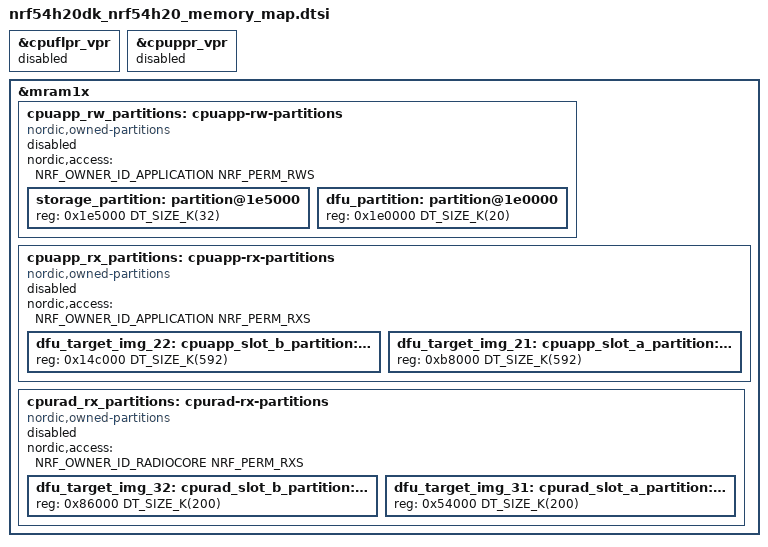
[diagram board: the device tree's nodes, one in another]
/*
 * Copyright (c) 2025 Nordic Semiconductor ASA
 *
 * SPDX-License-Identifier: LicenseRef-Nordic-5-Clause
 */

/* Disable FLPR and PPR cores */
&cpuflpr_vpr {
	status = "disabled";
	/delete-property/ source-memory;
};

&cpuppr_vpr {
	status = "disabled";
	/delete-property/ source-memory;
};

/* Override all application and radio partitions */
/delete-node/ &cpurad_rx_partitions;
/delete-node/ &cpuapp_rx_partitions;
/delete-node/ &cpuapp_rw_partitions;

/**
 * nRF54H20 MRAM area from 0x54000 to 0x1ED000 can be partitioned according to
 * specific end product needs. This file shows how to completely redefine all
 * partitions in mentioned area. For convenience, partition(s) unrelated to
 * DFU/boot (i.e. storage_partition, utilized for application settings)
 * are also reflected.
 *
 * Attention! Partitions are not updateable over the air, therefore must be
 * defined in a way that anticipated future image grow is reflected.
 *
 * ________________________ 0x200000
 * | Nordic (reserved)    |    76 kB
 * +----------------------+ 0x1ed000
 * | Application (RWS)    |
 * |  __________________  |
 * | | Settings/storage | |    32 kB
 * | +------------------+ | 0x1e5000
 * | | DFU partition    | |
 * | |__________________| |    20 kB
 * +----------------------+ 0x1e0000
 * | Application (RXS)    |
 * |  ___________________ |
 * | | Slot B           | |   592 kB
 * | +------------------+ | 0x14c000
 * | | Slot A           | |
 * | |__________________| |   592 kB
 * +----------------------+ 0x0b8000
 * | Radio (RXS)          |
 * |  ___________________ |
 * | | Slot B           | |   200 kB
 * | +------------------+ | 0x086000
 * | | Slot A           | |
 * | |__________________| |   200 kB
 * +----------------------+ 0x054000
 * | Nordic (reserved)    |   336 kB
 * |______________________| 0x000000
 */

&mram1x {
	cpuapp_rw_partitions: cpuapp-rw-partitions {
		compatible = "nordic,owned-partitions", "fixed-partitions";
		status = "disabled";
		nordic,access = <NRF_OWNER_ID_APPLICATION NRF_PERM_RWS>;
		#address-cells = <1>;
		#size-cells = <1>;

		/* Application-controlled NVM data. Size/location should be adjusted
		 * to end-product needs. Partition can be completely removed if
		 * it is not needed by the end product.
		 */
		storage_partition: partition@1e5000 {
			reg = < 0x1e5000 DT_SIZE_K(32) >;
		};

		/* DFU Partition shall be large enough to hold an envelope with candidate
		 * manifests. It is not recommended to decrease it below proposed 20kB,
		 * as it may affect device updateability.
		 */
		dfu_partition: partition@1e0000 {
			reg = < 0x1e0000 DT_SIZE_K(20) >;
		};
	};

	cpuapp_rx_partitions: cpuapp-rx-partitions {
		compatible = "nordic,owned-partitions", "fixed-partitions";
		status = "disabled";
		nordic,access = <NRF_OWNER_ID_APPLICATION NRF_PERM_RXS>;
		#address-cells = < 0x1 >;
		#size-cells = < 0x1 >;

		dfu_target_img_22: cpuapp_slot_b_partition: partition@14c000 {
			reg = < 0x14c000 DT_SIZE_K(592) >;
		};

		dfu_target_img_21: cpuapp_slot_a_partition: partition@b8000 {
			reg = < 0xb8000 DT_SIZE_K(592) >;
		};
	};

	cpurad_rx_partitions: cpurad-rx-partitions {
		compatible = "nordic,owned-partitions", "fixed-partitions";
		status = "disabled";
		nordic,access = <NRF_OWNER_ID_RADIOCORE NRF_PERM_RXS>;
		#address-cells = <1>;
		#size-cells = <1>;

		dfu_target_img_32: cpurad_slot_b_partition: partition@86000 {
			reg = <0x86000 DT_SIZE_K(200)>;
		};

		dfu_target_img_31: cpurad_slot_a_partition: partition@54000 {
			reg = < 0x54000 DT_SIZE_K(200) >;
		};
	};
};
